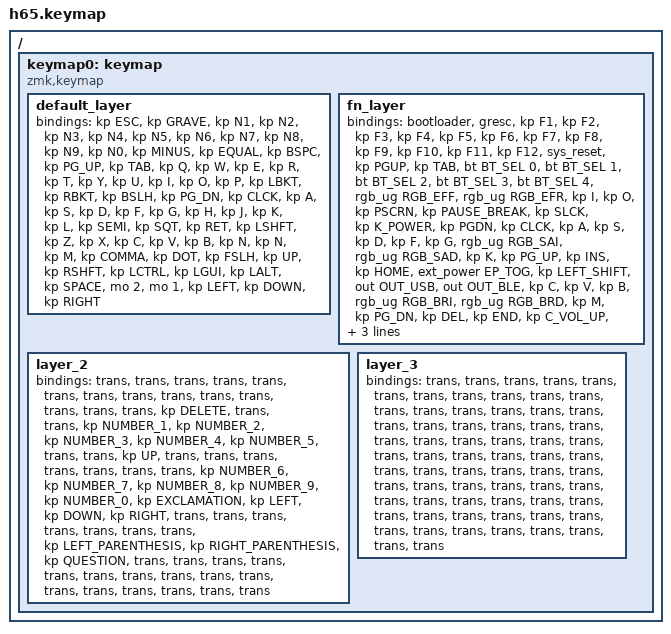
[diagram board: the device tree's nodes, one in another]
/*
 * Copyright (c) 2020 The ZMK Contributors
 *
 * SPDX-License-Identifier: MIT
 */

#include <behaviors.dtsi>
#include <dt-bindings/zmk/bt.h>
#include <dt-bindings/zmk/ext_power.h>
#include <dt-bindings/zmk/keys.h>
#include <dt-bindings/zmk/outputs.h>
#include <dt-bindings/zmk/rgb.h>

/ {
    keymap0: keymap {
        compatible = "zmk,keymap";

        default_layer {
            bindings = <
&kp ESC  &kp GRAVE  &kp N1  &kp N2  &kp N3  &kp N4  &kp N5  &kp N6  &kp N7  &kp N8  &kp N9  &kp N0  &kp MINUS  &kp EQUAL  &kp BSPC  &kp PG_UP  &kp TAB  &kp Q  &kp W  &kp E  &kp R  &kp T  &kp Y  &kp U  &kp I  &kp O  &kp P  &kp LBKT  &kp RBKT  &kp BSLH  &kp PG_DN  &kp CLCK  &kp A  &kp S  &kp D  &kp F  &kp G  &kp H  &kp J  &kp K  &kp L  &kp SEMI  &kp SQT  &kp RET  &kp LSHFT  &kp Z  &kp X  &kp C  &kp V  &kp B  &kp N  &kp N  &kp M  &kp COMMA  &kp DOT  &kp FSLH  &kp UP  &kp RSHFT  &kp LCTRL  &kp LGUI  &kp LALT  &kp SPACE  &mo 2  &mo 1  &kp LEFT  &kp DOWN  &kp RIGHT
            >;
        };

        fn_layer {
            bindings = <
&bootloader  &gresc  &kp F1  &kp F2  &kp F3  &kp F4  &kp F5  &kp F6  &kp F7  &kp F8  &kp F9  &kp F10  &kp F11  &kp F12  &sys_reset  &kp PGUP  &kp TAB  &bt BT_SEL 0  &bt BT_SEL 1  &bt BT_SEL 2  &bt BT_SEL 3  &bt BT_SEL 4  &rgb_ug RGB_EFF  &rgb_ug RGB_EFR  &kp I  &kp O  &kp PSCRN  &kp PAUSE_BREAK  &kp SLCK  &kp K_POWER  &kp PGDN  &kp CLCK  &kp A  &kp S  &kp D  &kp F  &kp G  &rgb_ug RGB_SAI  &rgb_ug RGB_SAD  &kp K  &kp PG_UP  &kp INS  &kp HOME  &ext_power EP_TOG  &kp LEFT_SHIFT  &out OUT_USB  &out OUT_BLE  &kp C  &kp V  &kp B  &rgb_ug RGB_BRI  &rgb_ug RGB_BRD  &kp M  &kp PG_DN  &kp DEL  &kp END  &kp C_VOL_UP  &kp C_PLAY_PAUSE  &kp LCTRL  &kp LEFT_WIN  &kp LALT  &bt BT_CLR  &lt 1 BACKSPACE  &mo 1  &kp C_PREVIOUS  &kp C_VOL_DN  &kp C_NEXT
            >;
        };

        layer_2 {
            bindings = <
&trans  &trans  &trans  &trans  &trans  &trans  &trans  &trans  &trans  &trans  &trans  &trans  &trans  &trans  &kp DELETE  &trans  &trans  &kp NUMBER_1  &kp NUMBER_2  &kp NUMBER_3  &kp NUMBER_4  &kp NUMBER_5  &trans  &trans  &kp UP  &trans  &trans  &trans  &trans  &trans  &trans  &trans  &kp NUMBER_6  &kp NUMBER_7  &kp NUMBER_8  &kp NUMBER_9  &kp NUMBER_0  &kp EXCLAMATION  &kp LEFT  &kp DOWN  &kp RIGHT  &trans  &trans  &trans  &trans  &trans  &trans  &trans  &kp LEFT_PARENTHESIS  &kp RIGHT_PARENTHESIS  &kp QUESTION  &trans  &trans  &trans  &trans  &trans  &trans  &trans  &trans  &trans  &trans  &trans  &trans  &trans  &trans  &trans  &trans
            >;
        };

        layer_3 {
            bindings = <
&trans  &trans  &trans  &trans  &trans  &trans  &trans  &trans  &trans  &trans  &trans  &trans  &trans  &trans  &trans  &trans  &trans  &trans  &trans  &trans  &trans  &trans  &trans  &trans  &trans  &trans  &trans  &trans  &trans  &trans  &trans  &trans  &trans  &trans  &trans  &trans  &trans  &trans  &trans  &trans  &trans  &trans  &trans  &trans  &trans  &trans  &trans  &trans  &trans  &trans  &trans  &trans  &trans  &trans  &trans  &trans  &trans  &trans  &trans  &trans  &trans  &trans  &trans  &trans  &trans  &trans  &trans
            >;
        };
    };
};
